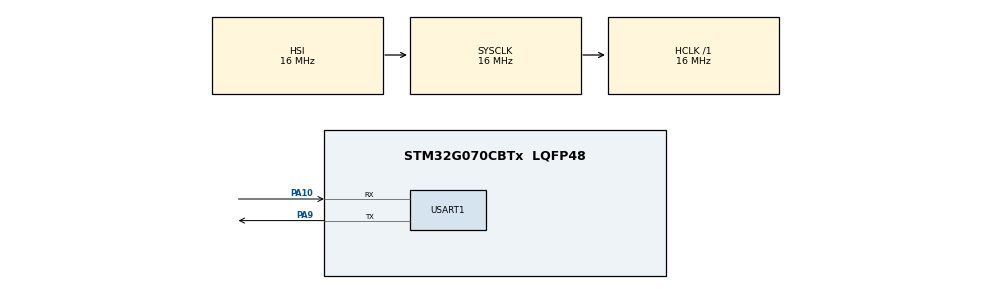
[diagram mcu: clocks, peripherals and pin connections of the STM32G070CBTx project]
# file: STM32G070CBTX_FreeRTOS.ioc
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FREERTOS.Tasks01=defaultTask,24,128,StartDefaultTask,Default,NULL,Dynamic,NULL,NULL
Mcu.Family=STM32G0
Mcu.Name=STM32G070CBTx
Mcu.Package=LQFP48
PA10.Mode=Asynchronous
PA10.Signal=USART1_RX
PA9\ [PA11].Mode=Asynchronous
PA9\ [PA11].Signal=USART1_TX
ProjectManager.HeapSize=0x200
ProjectManager.StackSize=0x400
ProjectManager.TargetToolchain=STM32CubeIDE
RCC.AHBFreq_Value=16000000
RCC.CortexFreq_Value=16000000
RCC.EXTERNAL_CLOCK_VALUE=48000
RCC.HCLKFreq_Value=16000000
RCC.HSE_VALUE=8000000
RCC.HSI_VALUE=16000000
RCC.LSE_VALUE=32768
RCC.SYSCLKFreq_VALUE=16000000
RCC.VCOOutputFreq_Value=128000000
USART1.VirtualMode-Asynchronous=VM_ASYNC
VP_FREERTOS_VS_CMSIS_V2.Mode=CMSIS_V2
VP_SYS_VS_PINREMAP.Mode=PINREMAP
board=custom

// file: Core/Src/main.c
/* USER CODE BEGIN Header */
/**
 ******************************************************************************
 * @file           : main.c
 * @brief          : Main program body
 ******************************************************************************
 * @attention
 *
 * Copyright (c) 2026 STMicroelectronics.
 * All rights reserved.
 *
 * This software is licensed under terms that can be found in the LICENSE file
 * in the root directory of this software component.
 * If no LICENSE file comes with this software, it is provided AS-IS.
 *
 ******************************************************************************
 */
/* USER CODE END Header */
#include "main.h"
#include "cmsis_os.h"

/* USER CODE BEGIN Includes */
#include <stdint.h>
#include <stdio.h>
/* USER CODE END Includes */

/* USER CODE BEGIN PM */
#define MS2TICKS(ms) ((ms * osKernelGetTickFreq()) / 1000)
#define EVT_GPIO_PRESSED 0x01
/* USER CODE END PM */

UART_HandleTypeDef huart1;

/* Definitions for defaultTask */
osThreadId_t config_task_handle;
const osThreadAttr_t config_task_attributes = {
    .name = "config_task",
    .priority = (osPriority_t)osPriorityNormal,
    .stack_size = 128 * 4};

void SystemClock_Config(void);
static void MX_GPIO_Init(void);
static void MX_USART1_UART_Init(void);
void config_task_handler(void *argument);

int main(void)
{

  /* MCU Configuration--------------------------------------------------------*/

  /* Reset of all peripherals, Initializes the Flash interface and the Systick. */
  HAL_Init();

  /* Configure the system clock */
  SystemClock_Config();

  /* Initialize all configured peripherals */
  MX_GPIO_Init();
  MX_USART1_UART_Init();

  /* Init scheduler */
  osKernelInitialize();

  /* Create the thread(s) */
  /* creation of defaultTask */
  config_task_handle = osThreadNew(config_task_handler, NULL, &config_task_attributes);

  /* Start scheduler */
  osKernelStart();

  /* We should never get here as control is now taken by the scheduler */

  /* Infinite loop */
  while (1)
  {

  }
}

void SystemClock_Config(void)
{
  RCC_OscInitTypeDef RCC_OscInitStruct = {0};
  RCC_ClkInitTypeDef RCC_ClkInitStruct = {0};

  /** Configure the main internal regulator output voltage
   */
  HAL_PWREx_ControlVoltageScaling(PWR_REGULATOR_VOLTAGE_SCALE1);

  /** Initializes the RCC Oscillators according to the specified parameters
   * in the RCC_OscInitTypeDef structure.
   */
  RCC_OscInitStruct.OscillatorType = RCC_OSCILLATORTYPE_HSI;
  RCC_OscInitStruct.HSIState = RCC_HSI_ON;
  RCC_OscInitStruct.HSIDiv = RCC_HSI_DIV1;
  RCC_OscInitStruct.HSICalibrationValue = RCC_HSICALIBRATION_DEFAULT;
  RCC_OscInitStruct.PLL.PLLState = RCC_PLL_NONE;
  if (HAL_RCC_OscConfig(&RCC_OscInitStruct) != HAL_OK)
  {
    Error_Handler();
  }

  /** Initializes the CPU, AHB and APB buses clocks
   */
  RCC_ClkInitStruct.ClockType = RCC_CLOCKTYPE_HCLK | RCC_CLOCKTYPE_SYSCLK | RCC_CLOCKTYPE_PCLK1;
  RCC_ClkInitStruct.SYSCLKSource = RCC_SYSCLKSOURCE_HSI;
  RCC_ClkInitStruct.AHBCLKDivider = RCC_SYSCLK_DIV1;
  RCC_ClkInitStruct.APB1CLKDivider = RCC_HCLK_DIV1;

  if (HAL_RCC_ClockConfig(&RCC_ClkInitStruct, FLASH_LATENCY_0) != HAL_OK)
  {
    Error_Handler();
  }
}

static void MX_USART1_UART_Init(void)
{

  huart1.Instance = USART1;
  huart1.Init.BaudRate = 115200;
  huart1.Init.WordLength = UART_WORDLENGTH_8B;
  huart1.Init.StopBits = UART_STOPBITS_1;
  huart1.Init.Parity = UART_PARITY_NONE;
  huart1.Init.Mode = UART_MODE_TX_RX;
  huart1.Init.HwFlowCtl = UART_HWCONTROL_NONE;
  huart1.Init.OverSampling = UART_OVERSAMPLING_16;
  huart1.Init.OneBitSampling = UART_ONE_BIT_SAMPLE_DISABLE;
  huart1.Init.ClockPrescaler = UART_PRESCALER_DIV1;
  huart1.AdvancedInit.AdvFeatureInit = UART_ADVFEATURE_NO_INIT;
  if (HAL_UART_Init(&huart1) != HAL_OK)
  {
    Error_Handler();
  }
  if (HAL_UARTEx_SetTxFifoThreshold(&huart1, UART_TXFIFO_THRESHOLD_1_8) != HAL_OK)
  {
    Error_Handler();
  }
  if (HAL_UARTEx_SetRxFifoThreshold(&huart1, UART_RXFIFO_THRESHOLD_1_8) != HAL_OK)
  {
    Error_Handler();
  }
  if (HAL_UARTEx_DisableFifoMode(&huart1) != HAL_OK)
  {
    Error_Handler();
  }
}

static void MX_GPIO_Init(void)
{
  GPIO_InitTypeDef GPIO_InitStruct = {0};

  /* GPIO Ports Clock Enable */
  __HAL_RCC_GPIOA_CLK_ENABLE();

  /*Configure GPIO pin : CFG_SW_Pin */
  GPIO_InitStruct.Pin = CFG_SW_Pin;
  GPIO_InitStruct.Mode = GPIO_MODE_IT_FALLING;
  GPIO_InitStruct.Pull = GPIO_PULLUP;
  HAL_GPIO_Init(CFG_SW_GPIO_Port, &GPIO_InitStruct);

  /* EXTI interrupt init*/
  HAL_NVIC_SetPriority(EXTI4_15_IRQn, 3, 0);
  HAL_NVIC_EnableIRQ(EXTI4_15_IRQn);

}

/* USER CODE BEGIN 4 */
int _write(int file, char *ptr, int len)
{
  HAL_UART_Transmit(&huart1, (uint8_t *)ptr, len, HAL_MAX_DELAY);
  return len;
}

void HAL_GPIO_EXTI_Falling_Callback(uint16_t GPIO_Pin)
{
  if (GPIO_Pin == CFG_SW_Pin)
  {
    osThreadFlagsSet(config_task_handle, 0x01);
  }
  else
  {
    __NOP();
  }
}

/* USER CODE END 4 */

void config_task_handler(void *argument)
{
  /* USER CODE BEGIN 5 */
  uint32_t flags;
  printf("config-user-started\r\n");
  /* Infinite loop */
  for (;;)
  {
    flags = osThreadFlagsWait(EVT_GPIO_PRESSED, osFlagsWaitAny, osWaitForever);
    if (flags & EVT_GPIO_PRESSED)
    {
      printf("Button Pressed!\r\n");
    }
  }
  /* USER CODE END 5 */
}

void HAL_TIM_PeriodElapsedCallback(TIM_HandleTypeDef *htim)
{
  if (htim->Instance == TIM6)
  {
    HAL_IncTick();
  }
}

void Error_Handler(void)
{
  __disable_irq();
  while (1)
  {
  }
}
